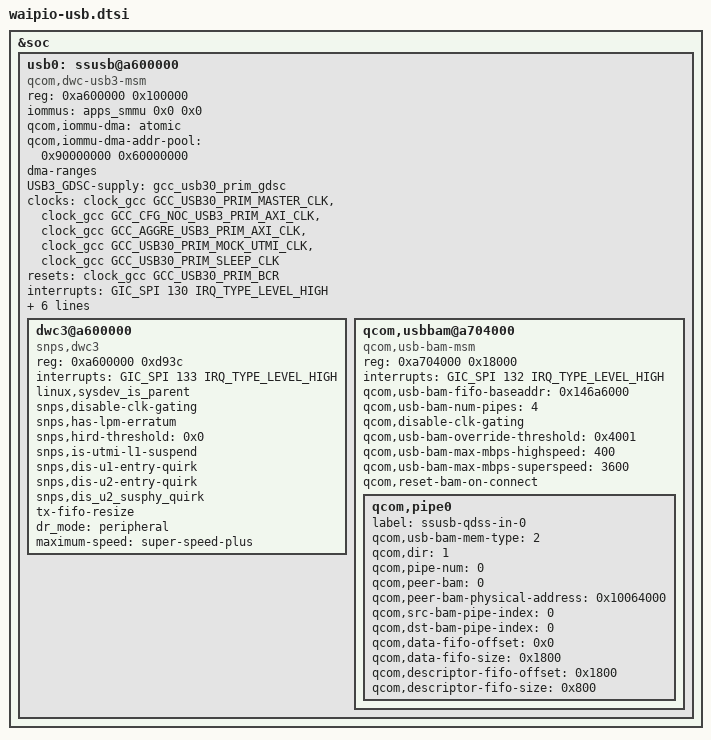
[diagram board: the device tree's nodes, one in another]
#include <dt-bindings/clock/qcom,gcc-waipio.h>

&soc {
	usb0: ssusb@a600000 {
		compatible = "qcom,dwc-usb3-msm";
		reg = <0xa600000 0x100000>;
		reg-names = "core_base";

		iommus = <&apps_smmu 0x0 0x0>;
		qcom,iommu-dma = "atomic";
		qcom,iommu-dma-addr-pool = <0x90000000 0x60000000>;

		#address-cells = <1>;
		#size-cells = <1>;
		ranges;
		dma-ranges;

		USB3_GDSC-supply = <&gcc_usb30_prim_gdsc>;
		clocks = <&clock_gcc GCC_USB30_PRIM_MASTER_CLK>,
			<&clock_gcc GCC_CFG_NOC_USB3_PRIM_AXI_CLK>,
			<&clock_gcc GCC_AGGRE_USB3_PRIM_AXI_CLK>,
			<&clock_gcc GCC_USB30_PRIM_MOCK_UTMI_CLK>,
			<&clock_gcc GCC_USB30_PRIM_SLEEP_CLK>;
		clock-names = "core_clk", "iface_clk", "bus_aggr_clk",
					"utmi_clk", "sleep_clk";

		resets = <&clock_gcc GCC_USB30_PRIM_BCR>;
		reset-names = "core_reset";

		interrupts = <GIC_SPI 130 IRQ_TYPE_LEVEL_HIGH>;
		interrupt-names = "pwr_event_irq";

		qcom,core-clk-rate = <200000000>;
		qcom,core-clk-rate-hs = <66666667>;
		qcom,num-gsi-evt-buffs = <0x3>;
		qcom,gsi-reg-offset =
			<0x0fc /* GSI_GENERAL_CFG */
			0x110 /* GSI_DBL_ADDR_L */
			0x120 /* GSI_DBL_ADDR_H */
			0x130 /* GSI_RING_BASE_ADDR_L */
			0x144 /* GSI_RING_BASE_ADDR_H */
			0x1a4>; /* GSI_IF_STS */
		qcom,dwc-usb3-msm-tx-fifo-size = <27696>;

		dwc3@a600000 {
			compatible = "snps,dwc3";
			reg = <0xa600000 0xd93c>;
			interrupts = <GIC_SPI 133 IRQ_TYPE_LEVEL_HIGH>;
			linux,sysdev_is_parent;
			snps,disable-clk-gating;
			snps,has-lpm-erratum;
			snps,hird-threshold = /bits/ 8 <0x0>;
			snps,is-utmi-l1-suspend;
			snps,dis-u1-entry-quirk;
			snps,dis-u2-entry-quirk;
			snps,dis_u2_susphy_quirk;
			tx-fifo-resize;
			dr_mode = "peripheral";
			maximum-speed = "super-speed-plus";
		};

		qcom,usbbam@a704000 {
			compatible = "qcom,usb-bam-msm";
			reg = <0xa704000 0x18000>;
			interrupts = <GIC_SPI 132 IRQ_TYPE_LEVEL_HIGH>;

			qcom,usb-bam-fifo-baseaddr = <0x146a6000>;
			qcom,usb-bam-num-pipes = <4>;
			qcom,disable-clk-gating;
			qcom,usb-bam-override-threshold = <0x4001>;
			qcom,usb-bam-max-mbps-highspeed = <400>;
			qcom,usb-bam-max-mbps-superspeed = <3600>;
			qcom,reset-bam-on-connect;

			qcom,pipe0 {
				label = "ssusb-qdss-in-0";
				qcom,usb-bam-mem-type = <2>;
				qcom,dir = <1>;
				qcom,pipe-num = <0>;
				qcom,peer-bam = <0>;
				qcom,peer-bam-physical-address = <0x10064000>;
				qcom,src-bam-pipe-index = <0>;
				qcom,dst-bam-pipe-index = <0>;
				qcom,data-fifo-offset = <0x0>;
				qcom,data-fifo-size = <0x1800>;
				qcom,descriptor-fifo-offset = <0x1800>;
				qcom,descriptor-fifo-size = <0x800>;
			};
		};
	};
};
